# ATmega64C1 device description
Architecture: AVR8; Family: megaAVR
Registers are 8-bit, access not given, no defined reset value unless marked. A register's access mark holds for its fields unless they carry their own. Offsets are from the block's base; [hi:lo] are bit positions.

## LOCKBIT — Lockbits
Instances: LOCKBIT 0 in lockbits
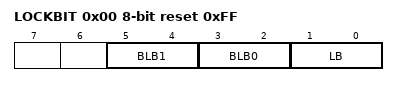
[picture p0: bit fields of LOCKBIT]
0x00 LOCKBIT reset 0xFF
  [5:4] BLB1 — Boot Loader Protection Mode
    0=LPM_SPM_DISABLE (LPM and SPM prohibited in Boot Section); 1=LPM_DISABLE (LPM prohibited in Boot Section); 2=SPM_DISABLE (SPM prohibited in Boot Section); 3=NO_LOCK (No lock on SPM and LPM in Boot Section)
  [3:2] BLB0 — Boot Loader Protection Mode
    0=LPM_SPM_DISABLE (LPM and SPM prohibited in Application Section); 1=LPM_DISABLE (LPM prohibited in Application Section); 2=SPM_DISABLE (SPM prohibited in Application Section); 3=NO_LOCK (No lock on SPM and LPM in Application Section)
  [1:0] LB — Memory Lock
    0=PROG_VER_DISABLED (Further programming and verification disabled); 2=PROG_DISABLED (Further programming disabled); 3=NO_LOCK (No memory lock features enabled)

## PORTB — I/O Port
Instances: PORTB 0x00
0x23 PINB — Port B Input Pins
0x24 DDRB — Port B Data Direction Register
0x25 PORTB — Port B Data Register

## PORTC — I/O Port
Instances: PORTC 0x00
0x26 PINC — Port C Input Pins
0x27 DDRC — Port C Data Direction Register
0x28 PORTC — Port C Data Register

## PORTD — I/O Port
Instances: PORTD 0x00
0x29 PIND — Port D Input Pins
0x2A DDRD — Port D Data Direction Register
0x2B PORTD — Port D Data Register

## PORTE — I/O Port
Instances: PORTE 0x00
0x2C PINE bits used 2:0 — Port E Input Pins
0x2D DDRE bits used 2:0 — Port E Data Direction Register
0x2E PORTE bits used 2:0 — Port E Data Register

## CAN — Controller Area Network
Instances: CAN 0x00
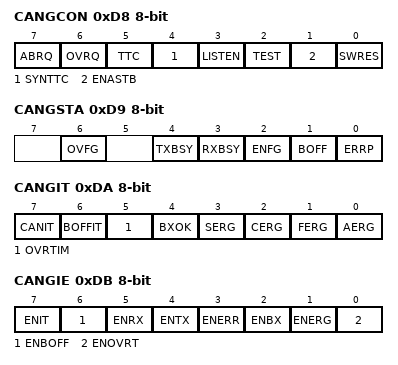
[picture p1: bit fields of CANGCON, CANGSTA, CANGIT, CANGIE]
0xD8 CANGCON — CAN General Control Register
  [7] ABRQ — Abort Request
  [6] OVRQ — Overload Frame Request
  [5] TTC — Time Trigger Communication
  [4] SYNTTC — Synchronization of TTC
  [3] LISTEN — Listening Mode
  [2] TEST — Test Mode
  [1] ENASTB — Enable / Standby
  [0] SWRES — Software Reset Request
0xD9 CANGSTA — CAN General Status Register
  [6] OVFG — Overload Frame Flag
  [4] TXBSY — Transmitter Busy
  [3] RXBSY — Receiver Busy
  [2] ENFG — Enable Flag
  [1] BOFF — Bus Off Mode
  [0] ERRP — Error Passive Mode
0xDA CANGIT — CAN General Interrupt Register Flags
  [7] CANIT — General Interrupt Flag
  [6] BOFFIT — Bus Off Interrupt Flag
  [5] OVRTIM — Overrun CAN Timer Flag
  [4] BXOK — Burst Receive Interrupt Flag
  [3] SERG — Stuff Error General Flag
  [2] CERG — CRC Error General Flag
  [1] FERG — Form Error General Flag
  [0] AERG — Ackknowledgement Error General Flag
0xDB CANGIE — CAN General Interrupt Enable Register
  [7] ENIT — Enable all Interrupts
  [6] ENBOFF — Enable Bus Off Interrupt
  [5] ENRX — Enable Receive Interrupt
  [4] ENTX — Enable Transmitt Interrupt
  [3] ENERR — Enable MOb Error Interrupt
  [2] ENBX — Enable Burst Receive Interrupt
  [1] ENERG — Enable General Error Interrupt
  [0] ENOVRT — Enable CAN Timer Overrun Interrupt
0xDC CANEN2 — Enable MOb Register 2
  [5:0] ENMOB — Enable MObs
0xDD CANEN1 — Enable MOb Register 1(empty)
0xDE CANIE2 — Enable Interrupt MOb Register 2
  [5:0] IEMOB — Interrupt Enable MObs
0xDF CANIE1 — Enable Interrupt MOb Register 1 (empty)
0xE0 CANSIT2 — CAN Status Interrupt MOb Register 2
  [5:0] SIT — Status of Interrupt MObs
0xE1 CANSIT1 — CAN Status Interrupt MOb Register 1 (empty)
0xE2 CANBT1 — CAN Bit Timing Register 1
  [6:1] BRP — Baud Rate Prescaler bits
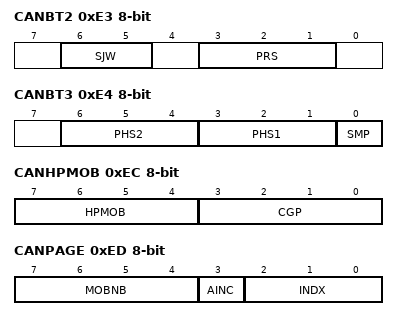
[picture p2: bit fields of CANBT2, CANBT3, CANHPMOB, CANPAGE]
0xE3 CANBT2 — CAN Bit Timing Register 2
  [6:5] SJW — Re-Sync Jump Width bits
  [3:1] PRS — Propagation Time Segment bits
0xE4 CANBT3 — CAN Bit Timing Register 3
  [6:4] PHS2 — Phase Segment 2 bits
  [3:1] PHS1 — Phase Segment 1 bits
  [0] SMP — Sample Type
0xE5 CANTCON — Timer Control Register
0xE6 CANTIML — Timer Register Low
0xE7 CANTIMH — Timer Register High
0xE8 CANTTCL — TTC Timer Register Low
0xE9 CANTTCH — TTC Timer Register High
0xEA CANTEC — Transmit Error Counter Register
0xEB CANREC — Receive Error Counter Register
0xEC CANHPMOB — Highest Priority MOb Register
  [7:4] HPMOB — Highest Priority MOb Number bits
  [3:0] CGP — CAN General Purpose bits
0xED CANPAGE — Page MOb Register
  [7:4] MOBNB — MOb Number bits
  [3] AINC — MOb Data Buffer Auto Increment (Active Low)
  [2:0] INDX — Data Buffer Index bits
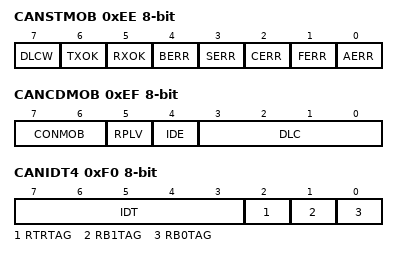
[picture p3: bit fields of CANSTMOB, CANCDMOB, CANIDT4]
0xEE CANSTMOB — MOb Status Register
  [7] DLCW — Data Length Code Warning on MOb
  [6] TXOK — Transmit OK on MOb
  [5] RXOK — Receive OK on MOb
  [4] BERR — Bit Error on MOb
  [3] SERR — Stuff Error on MOb
  [2] CERR — CRC Error on MOb
  [1] FERR — Form Error on MOb
  [0] AERR — Ackknowledgement Error on MOb
0xEF CANCDMOB — MOb Control and DLC Register
  [7:6] CONMOB — MOb Config bits
  [5] RPLV — Reply Valid
  [4] IDE — Identifier Extension
  [3:0] DLC — Data Length Code bits
0xF0 CANIDT4 — Identifier Tag Register 4
  [7:3] IDT, [2] RTRTAG, [1] RB1TAG, [0] RB0TAG
0xF1 CANIDT3 — Identifier Tag Register 3
0xF2 CANIDT2 — Identifier Tag Register 2
0xF3 CANIDT1 — Identifier Tag Register 1
0xF4 CANIDM4 bits used 7:2,0 — Identifier Mask Register 4
0xF5 CANIDM3 — Identifier Mask Register 3
0xF6 CANIDM2 — Identifier Mask Register 2
0xF7 CANIDM1 — Identifier Mask Register 1
0xF8 CANSTML — Time Stamp Register Low
0xF9 CANSTMH — Time Stamp Register High
0xFA CANMSG — Message Data Register
